VERSION ""

NS_ :

BS_:

BU_:

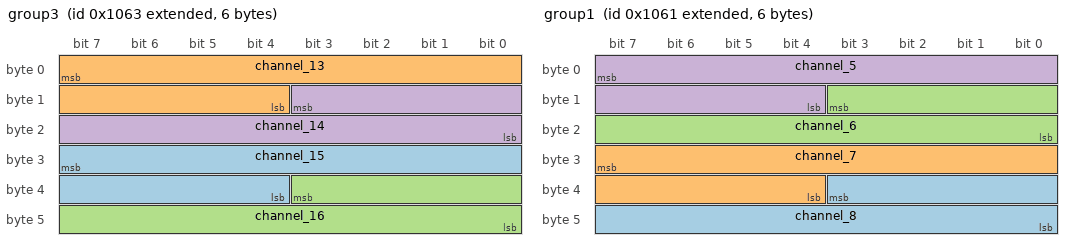
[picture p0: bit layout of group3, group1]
BO_ 2147487843 group3: 6 Vector__XXX
 SG_ channel_15 : 31|12@0+ (1,0) [0|4095] "" Vector__XXX
 SG_ channel_13 : 7|12@0+ (1,0) [0|4095] "" Vector__XXX
 SG_ channel_16 : 35|12@0+ (1,0) [0|4095] "" Vector__XXX
 SG_ channel_14 : 11|12@0+ (1,0) [0|4095] "" Vector__XXX

BO_ 2147487841 group1: 6 Vector__XXX
 SG_ channel_8 : 35|12@0+ (1,0) [0|4095] "" Vector__XXX
 SG_ channel_7 : 31|12@0+ (1,0) [0|4095] "" Vector__XXX
 SG_ channel_6 : 11|12@0+ (1,0) [0|4095] "" Vector__XXX
 SG_ channel_5 : 7|12@0+ (1,0) [0|4095] "" Vector__XXX

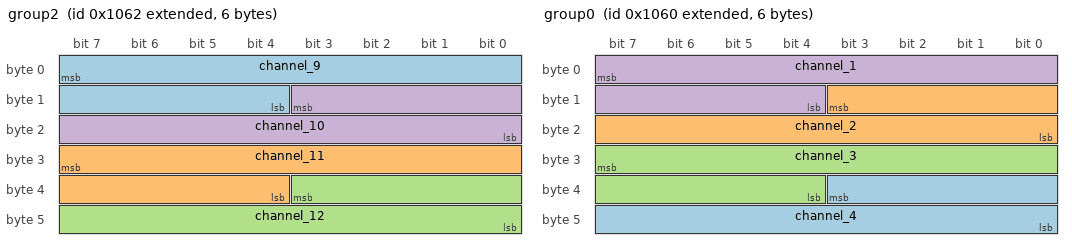
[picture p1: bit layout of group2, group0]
BO_ 2147487842 group2: 6 Vector__XXX
 SG_ channel_9 : 7|12@0+ (1,0) [0|4095] "" Vector__XXX
 SG_ channel_11 : 31|12@0+ (1,0) [0|4095] "" Vector__XXX
 SG_ channel_12 : 35|12@0+ (1,0) [0|4095] "" Vector__XXX
 SG_ channel_10 : 11|12@0+ (1,0) [0|4095] "" Vector__XXX

BO_ 2147487840 group0: 6 Vector__XXX
 SG_ channel_4 : 35|12@0+ (1,0) [0|4095] "" Vector__XXX
 SG_ channel_2 : 11|12@0+ (1,0) [0|4095] "" Vector__XXX
 SG_ channel_3 : 31|12@0+ (1,0) [0|4095] "" Vector__XXX
 SG_ channel_1 : 7|12@0+ (1,0) [0|4095] "" Vector__XXX

BA_DEF_  "BusType" STRING ;
BA_DEF_ BO_  "GenMsgCycleTime" INT 0 0;
BA_DEF_DEF_  "BusType" "CAN";
BA_DEF_DEF_  "GenMsgCycleTime" 0;
BA_ "GenMsgCycleTime" BO_ 2147487843 4;
BA_ "GenMsgCycleTime" BO_ 2147487841 4;
BA_ "GenMsgCycleTime" BO_ 2147487842 4;
BA_ "GenMsgCycleTime" BO_ 2147487840 4;
